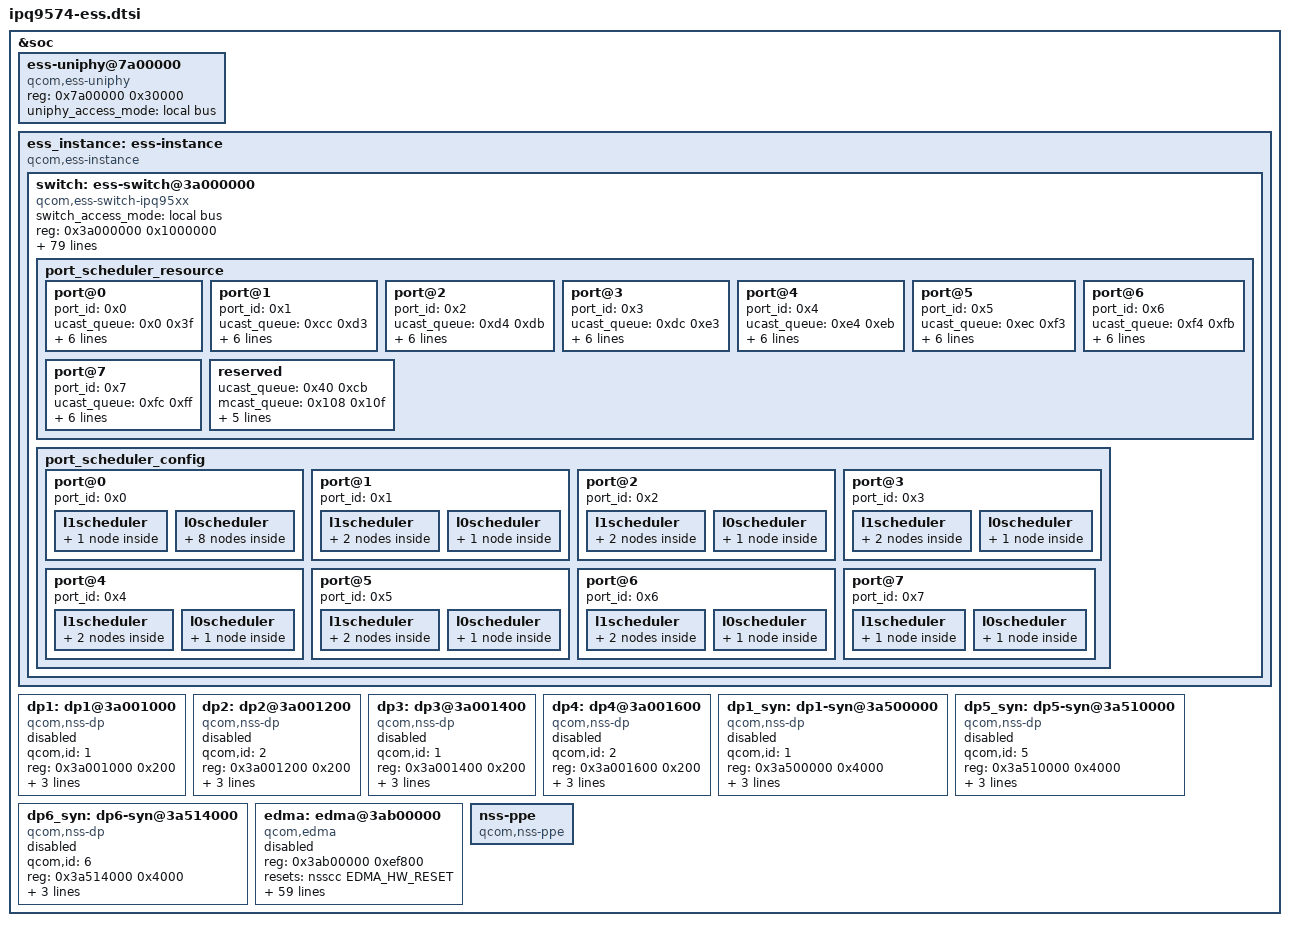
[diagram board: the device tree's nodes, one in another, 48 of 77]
#include <dt-bindings/net/qcom-ipq-ess.h>

&soc {
	ess-uniphy@7a00000 {
		compatible = "qcom,ess-uniphy";
		reg = <0x7a00000 0x30000>;
		uniphy_access_mode = "local bus";
	};

	ess_instance: ess-instance {
		compatible = "qcom,ess-instance";

		switch: ess-switch@3a000000 {
			compatible = "qcom,ess-switch-ipq95xx";
			switch_access_mode = "local bus";
			reg = <0x3a000000 0x1000000>;
			clocks = <&gcc GCC_CMN_12GPLL_AHB_CLK>,
				<&gcc GCC_CMN_12GPLL_SYS_CLK>,
				<&gcc GCC_UNIPHY0_AHB_CLK>,
				<&gcc GCC_UNIPHY0_SYS_CLK>,
				<&gcc GCC_UNIPHY1_AHB_CLK>,
				<&gcc GCC_UNIPHY1_SYS_CLK>,
				<&gcc GCC_UNIPHY2_AHB_CLK>,
				<&gcc GCC_UNIPHY2_SYS_CLK>,
				<&gcc GCC_NSSNOC_NSSCC_CLK>,
				<&gcc GCC_NSSCC_CLK>,
				<&gcc GCC_NSSNOC_SNOC_1_CLK>,
				<&gcc GCC_NSSNOC_SNOC_CLK>,
				<&nsscc NSS_CC_PORT1_MAC_CLK>,
				<&nsscc NSS_CC_PORT2_MAC_CLK>,
				<&nsscc NSS_CC_PORT3_MAC_CLK>,
				<&nsscc NSS_CC_PORT4_MAC_CLK>,
				<&nsscc NSS_CC_PORT5_MAC_CLK>,
				<&nsscc NSS_CC_PORT6_MAC_CLK>,
				<&nsscc NSS_CC_PPE_SWITCH_CLK>,
				<&nsscc NSS_CC_PPE_SWITCH_CFG_CLK>,
				<&nsscc NSS_CC_NSSNOC_PPE_CLK>,
				<&nsscc NSS_CC_NSSNOC_PPE_CFG_CLK>,
				<&nsscc NSS_CC_PPE_EDMA_CLK>,
				<&nsscc NSS_CC_PPE_EDMA_CFG_CLK>,
				<&nsscc NSS_CC_PPE_SWITCH_IPE_CLK>,
				<&nsscc NSS_CC_PPE_SWITCH_BTQ_CLK>,
				<&nsscc NSS_CC_PORT1_RX_CLK>,
				<&nsscc NSS_CC_PORT1_TX_CLK>,
				<&nsscc NSS_CC_PORT2_RX_CLK>,
				<&nsscc NSS_CC_PORT2_TX_CLK>,
				<&nsscc NSS_CC_PORT3_RX_CLK>,
				<&nsscc NSS_CC_PORT3_TX_CLK>,
				<&nsscc NSS_CC_PORT4_RX_CLK>,
				<&nsscc NSS_CC_PORT4_TX_CLK>,
				<&nsscc NSS_CC_PORT5_RX_CLK>,
				<&nsscc NSS_CC_PORT5_TX_CLK>,
				<&nsscc NSS_CC_PORT6_RX_CLK>,
				<&nsscc NSS_CC_PORT6_TX_CLK>,
				<&nsscc NSS_CC_UNIPHY_PORT1_RX_CLK>,
				<&nsscc NSS_CC_UNIPHY_PORT1_TX_CLK>,
				<&nsscc NSS_CC_UNIPHY_PORT2_RX_CLK>,
				<&nsscc NSS_CC_UNIPHY_PORT2_TX_CLK>,
				<&nsscc NSS_CC_UNIPHY_PORT3_RX_CLK>,
				<&nsscc NSS_CC_UNIPHY_PORT3_TX_CLK>,
				<&nsscc NSS_CC_UNIPHY_PORT4_RX_CLK>,
				<&nsscc NSS_CC_UNIPHY_PORT4_TX_CLK>,
				<&nsscc NSS_CC_UNIPHY_PORT5_RX_CLK>,
				<&nsscc NSS_CC_UNIPHY_PORT5_TX_CLK>,
				<&nsscc NSS_CC_UNIPHY_PORT6_RX_CLK>,
				<&nsscc NSS_CC_UNIPHY_PORT6_TX_CLK>,
				<&nsscc NSS_CC_PORT5_RX_CLK_SRC>,
				<&nsscc NSS_CC_PORT5_TX_CLK_SRC>;

			clock-names = "cmn_ahb_clk",
				"cmn_sys_clk",
				"uniphy0_ahb_clk",
				"uniphy0_sys_clk",
				"uniphy1_ahb_clk",
				"uniphy1_sys_clk",
				"uniphy2_ahb_clk",
				"uniphy2_sys_clk",
				"gcc_nssnoc_nsscc_clk",
				"gcc_nsscc_clk",
				"gcc_nssnoc_snoc_1_clk",
				"gcc_nssnoc_snoc_clk",
				"port1_mac_clk",
				"port2_mac_clk",
				"port3_mac_clk",
				"port4_mac_clk",
				"port5_mac_clk",
				"port6_mac_clk",
				"nss_ppe_clk",
				"nss_ppe_cfg_clk",
				"nssnoc_ppe_clk",
				"nssnoc_ppe_cfg_clk",
				"nss_edma_clk",
				"nss_edma_cfg_clk",
				"nss_ppe_ipe_clk",
				"nss_ppe_btq_clk",
				"nss_port1_rx_clk", "nss_port1_tx_clk",
				"nss_port2_rx_clk", "nss_port2_tx_clk",
				"nss_port3_rx_clk", "nss_port3_tx_clk",
				"nss_port4_rx_clk", "nss_port4_tx_clk",
				"nss_port5_rx_clk", "nss_port5_tx_clk",
				"nss_port6_rx_clk", "nss_port6_tx_clk",
				"uniphy0_port1_rx_clk",
				"uniphy0_port1_tx_clk",
				"uniphy0_port2_rx_clk",
				"uniphy0_port2_tx_clk",
				"uniphy0_port3_rx_clk",
				"uniphy0_port3_tx_clk",
				"uniphy0_port4_rx_clk",
				"uniphy0_port4_tx_clk",
				"uniphy0_port5_rx_clk",
				"uniphy0_port5_tx_clk",
				"uniphy2_port6_rx_clk",
				"uniphy2_port6_tx_clk",
				"nss_port5_rx_clk_src",
				"nss_port5_tx_clk_src";

			resets =<&nsscc PPE_FULL_RESET>,
				<&nsscc UNIPHY0_SOFT_RESET>,
				<&gcc GCC_UNIPHY0_XPCS_RESET>,
				<&nsscc UNIPHY_PORT5_ARES>,
				<&gcc GCC_UNIPHY1_XPCS_RESET>,
				<&nsscc UNIPHY_PORT6_ARES>,
				<&gcc GCC_UNIPHY2_XPCS_RESET>,
				<&nsscc UNIPHY_PORT1_ARES>,
				<&nsscc UNIPHY_PORT2_ARES>,
				<&nsscc UNIPHY_PORT3_ARES>,
				<&nsscc UNIPHY_PORT4_ARES>,
				<&gcc GCC_UNIPHY0_SYS_RESET>,
				<&gcc GCC_UNIPHY1_SYS_RESET>,
				<&gcc GCC_UNIPHY2_SYS_RESET>,
				<&nsscc NSSPORT1_RESET>,
				<&nsscc NSSPORT2_RESET>,
				<&nsscc NSSPORT3_RESET>,
				<&nsscc NSSPORT4_RESET>,
				<&nsscc NSSPORT5_RESET>,
				<&nsscc NSSPORT6_RESET>,
				<&nsscc PORT1_MAC_ARES>,
				<&nsscc PORT2_MAC_ARES>,
				<&nsscc PORT3_MAC_ARES>,
				<&nsscc PORT4_MAC_ARES>,
				<&nsscc PORT5_MAC_ARES>,
				<&nsscc PORT6_MAC_ARES>;

			reset-names = "ppe_rst",
				"uniphy0_soft_rst",
				"uniphy0_xpcs_rst",
				"uniphy1_soft_rst",
				"uniphy1_xpcs_rst",
				"uniphy2_soft_rst",
				"uniphy2_xpcs_rst",
				"uniphy0_port1_dis",
				"uniphy0_port2_dis",
				"uniphy0_port3_dis",
				"uniphy0_port4_dis",
				"uniphy0_sys_rst",
				"uniphy1_sys_rst",
				"uniphy2_sys_rst",
				"nss_port1_rst",
				"nss_port2_rst",
				"nss_port3_rst",
				"nss_port4_rst",
				"nss_port5_rst",
				"nss_port6_rst",
				"nss_port1_mac_rst",
				"nss_port2_mac_rst",
				"nss_port3_mac_rst",
				"nss_port4_mac_rst",
				"nss_port5_mac_rst",
				"nss_port6_mac_rst";

			bm_tick_mode = <0>; /* bm tick mode */
			tm_tick_mode = <0>; /* tm tick mode */

			switch_cpu_bmp = <ESS_PORT0>;  /* cpu port bitmap */
			switch_inner_bmp = <ESS_PORT7>; /*inner port bitmap*/
			switch_mac_mode = <MAC_MODE_DISABLED>; /* mac mode for uniphy instance0*/
			switch_mac_mode1 = <MAC_MODE_DISABLED>; /* mac mode for uniphy instance1*/
			switch_mac_mode2 = <MAC_MODE_DISABLED>; /* mac mode for uniphy instance2*/

			mdio-bus = <&mdio>;

				port_scheduler_resource {

					port@0 {
						port_id = <0x0>;
						ucast_queue = <0x0 0x3f>;
						mcast_queue = <0x100 0x107>;
						l0sp = <0x0 0x0>;
						l0cdrr = <0x0 0x7>;
						l0edrr = <0x0 0x7>;
						l1cdrr = <0x0 0x0>;
						l1edrr = <0x0 0x0>;
					};

					port@1 {
						port_id = <0x1>;
						ucast_queue = <0xcc 0xd3>;
						mcast_queue = <0x110 0x113>;
						l0sp = <0x33 0x34>;
						l0cdrr = <0x6c 0x73>;
						l0edrr = <0x6c 0x73>;
						l1cdrr = <0x17 0x18>;
						l1edrr = <0x17 0x18>;
					};

					port@2 {
						port_id = <0x2>;
						ucast_queue = <0xd4 0xdb>;
						mcast_queue = <0x114 0x117>;
						l0sp = <0x35 0x36>;
						l0cdrr = <0x74 0x7b>;
						l0edrr = <0x74 0x7b>;
						l1cdrr = <0x19 0x1a>;
						l1edrr = <0x19 0x1a>;
					};

					port@3 {
						port_id = <0x3>;
						ucast_queue = <0xdc 0xe3>;
						mcast_queue = <0x118 0x11b>;
						l0sp = <0x37 0x38>;
						l0cdrr = <0x7c 0x83>;
						l0edrr = <0x7c 0x83>;
						l1cdrr = <0x1b 0x1c>;
						l1edrr = <0x1b 0x1c>;
					};

					port@4 {
						port_id = <0x4>;
						ucast_queue = <0xe4 0xeb>;
						mcast_queue = <0x11c 0x11f>;
						l0sp = <0x39 0x3a>;
						l0cdrr = <0x84 0x8b>;
						l0edrr = <0x84 0x8b>;
						l1cdrr = <0x1d 0x1e>;
						l1edrr = <0x1d 0x1e>;
					};

					port@5 {
						port_id = <0x5>;
						ucast_queue = <0xec 0xf3>;
						mcast_queue = <0x120 0x123>;
						l0sp = <0x3b 0x3c>;
						l0cdrr = <0x8c 0x93>;
						l0edrr = <0x8c 0x93>;
						l1cdrr = <0x1f 0x20>;
						l1edrr = <0x1f 0x20>;
					};

					port@6 {
						port_id = <0x6>;
						ucast_queue = <0xf4 0xfb>;
						mcast_queue = <0x124 0x127>;
						l0sp = <0x3d 0x3e>;
						l0cdrr = <0x94 0x9b>;
						l0edrr = <0x94 0x9b>;
						l1cdrr = <0x21 0x22>;
						l1edrr = <0x21 0x22>;
					};

					port@7 {
						port_id = <0x7>;
						ucast_queue = <0xfc 0xff>;
						mcast_queue = <0x128 0x12b>;
						l0sp = <0x3f 0x3f>;
						l0cdrr = <0x9c 0x9f>;
						l0edrr = <0x9c 0x9f>;
						l1cdrr = <0x23 0x23>;
						l1edrr = <0x23 0x23>;
					};

					reserved {
						ucast_queue = <0x40 0xcb>;
						mcast_queue = <0x108 0x10f>;
						l0sp = <0x1 0x32>;
						l0cdrr = <0x8 0x6b>;
						l0edrr = <0x8 0x6b>;
						l1cdrr = <0x1 0x16>;
						l1edrr = <0x1 0x16>;
					};
				};

				port_scheduler_config {

					port@0 {
						port_id = <0x0>;

						l1scheduler {

							group@0 {
								sp = <0x0>;
								cfg = <0x0 0x0 0x0 0x0>;
							};
						};

						l0scheduler {

							group@0 {
								ucast_queue = <0x0>;
								ucast_loop_pri = <0x8>;
								mcast_queue = <0x100>;
								cfg = <0x0 0x0 0x0 0x0 0x0>;
							};

							group@1 {
								ucast_queue = <0x8>;
								ucast_loop_pri = <0x8>;
								mcast_queue = <0x101>;
								cfg = <0x0 0x0 0x0 0x0 0x0>;
							};

							group@2 {
								ucast_queue = <0x10>;
								ucast_loop_pri = <0x8>;
								mcast_queue = <0x102>;
								cfg = <0x0 0x0 0x0 0x0 0x0>;
							};

							group@3 {
								ucast_queue = <0x18>;
								ucast_loop_pri = <0x8>;
								mcast_queue = <0x103>;
								cfg = <0x0 0x0 0x0 0x0 0x0>;
							};

							group@4 {
								ucast_queue = <0x20>;
								ucast_loop_pri = <0x8>;
								mcast_queue = <0x104>;
								cfg = <0x0 0x0 0x0 0x0 0x0>;
							};

							group@5 {
								ucast_queue = <0x28>;
								ucast_loop_pri = <0x8>;
								mcast_queue = <0x105>;
								cfg = <0x0 0x0 0x0 0x0 0x0>;
							};

							group@6 {
								ucast_queue = <0x30>;
								ucast_loop_pri = <0x8>;
								mcast_queue = <0x106>;
								cfg = <0x0 0x0 0x0 0x0 0x0>;
							};

							group@7 {
								ucast_queue = <0x38>;
								ucast_loop_pri = <0x8>;
								mcast_queue = <0x107>;
								cfg = <0x0 0x0 0x0 0x0 0x0>;
							};
						};
					};

					port@1 {
						port_id = <0x1>;

						l1scheduler {

							group@0 {
								sp = <0x33>;
								cfg = <0x0 0x17 0x0 0x17>;
							};

							group@1 {
								sp = <0x34>;
								cfg = <0x1 0x18 0x1 0x18>;
							};
						};

						l0scheduler {

							group@0 {
								ucast_queue = <0xcc>;
								ucast_loop_pri = <0x8>;
								ucast_max_pri = <0x4>;
								mcast_queue = <0x110>;
								mcast_loop_pri = <0x4>;
								cfg = <0x33 0x0 0x6c 0x0 0x6c>;
							};
						};
					};

					port@2 {
						port_id = <0x2>;

						l1scheduler {

							group@0 {
								sp = <0x35>;
								cfg = <0x0 0x19 0x0 0x19>;
							};

							group@1 {
								sp = <0x36>;
								cfg = <0x1 0x1a 0x1 0x1a>;
							};
						};

						l0scheduler {

							group@0 {
								ucast_queue = <0xd4>;
								ucast_loop_pri = <0x8>;
								ucast_max_pri = <0x4>;
								mcast_queue = <0x114>;
								mcast_loop_pri = <0x4>;
								cfg = <0x35 0x0 0x74 0x0 0x74>;
							};
						};
					};

					port@3 {
						port_id = <0x3>;

						l1scheduler {

							group@0 {
								sp = <0x37>;
								cfg = <0x0 0x1b 0x0 0x1b>;
							};

							group@1 {
								sp = <0x38>;
								cfg = <0x1 0x1c 0x1 0x1c>;
							};
						};

						l0scheduler {

							group@0 {
								ucast_queue = <0xdc>;
								ucast_loop_pri = <0x8>;
								ucast_max_pri = <0x4>;
								mcast_queue = <0x118>;
								mcast_loop_pri = <0x4>;
								cfg = <0x37 0x0 0x7c 0x0 0x7c>;
							};
						};
					};

					port@4 {
						port_id = <0x4>;

						l1scheduler {

							group@0 {
								sp = <0x39>;
								cfg = <0x0 0x1d 0x0 0x1d>;
							};

							group@1 {
								sp = <0x3a>;
								cfg = <0x1 0x1e 0x1 0x1e>;
							};
						};

						l0scheduler {

							group@0 {
								ucast_queue = <0xe4>;
								ucast_loop_pri = <0x8>;
								ucast_max_pri = <0x4>;
								mcast_queue = <0x11c>;
								mcast_loop_pri = <0x4>;
								cfg = <0x39 0x0 0x84 0x0 0x84>;
							};
						};
					};

					port@5 {
						port_id = <0x5>;

						l1scheduler {

							group@0 {
								sp = <0x3b>;
								cfg = <0x0 0x1f 0x0 0x1f>;
							};

							group@1 {
								sp = <0x3c>;
								cfg = <0x1 0x20 0x1 0x20>;
							};
						};

						l0scheduler {

							group@0 {
								ucast_queue = <0xec>;
								ucast_loop_pri = <0x8>;
								ucast_max_pri = <0x4>;
								mcast_queue = <0x120>;
								mcast_loop_pri = <0x4>;
								cfg = <0x3b 0x0 0x8c 0x0 0x8c>;
							};
						};
					};

					port@6 {
						port_id = <0x6>;

						l1scheduler {

							group@0 {
								sp = <0x3d>;
								cfg = <0x0 0x21 0x0 0x21>;
							};

							group@1 {
								sp = <0x3e>;
								cfg = <0x1 0x22 0x1 0x22>;
							};
						};

						l0scheduler {

							group@0 {
								ucast_queue = <0xf4>;
								ucast_loop_pri = <0x8>;
								ucast_max_pri = <0x4>;
								mcast_queue = <0x124>;
								mcast_loop_pri = <0x4>;
								cfg = <0x3d 0x0 0x94 0x0 0x94>;
							};
						};
					};

					port@7 {
						port_id = <0x7>;

						l1scheduler {

							group@0 {
								sp = <0x3f>;
								cfg = <0x0 0x23 0x0 0x23>;
							};
						};

						l0scheduler {

							group@0 {
								ucast_queue = <0xfc>;
								ucast_loop_pri = <0x4>;
								ucast_max_pri = <0x4>;
								mcast_queue = <0x128>;
								mcast_loop_pri = <0x4>;
								cfg = <0x3f 0x0 0x9c 0x0 0x9c>;
							};
						};
					};
				};
		};
	};

	dp1: dp1@3a001000 {
		device_type = "network";
		compatible = "qcom,nss-dp";
		qcom,id = <1>;
		reg = <0x3a001000 0x200>;
		qcom,mactype = <0>;
		local-mac-address = [000000000000];
		phy-mode = "sgmii";
		status = "disabled";
	};

	dp2: dp2@3a001200 {
		device_type = "network";
		compatible = "qcom,nss-dp";
		qcom,id = <2>;
		reg = <0x3a001200 0x200>;
		qcom,mactype = <0>;
		local-mac-address = [000000000000];
		phy-mode = "sgmii";
		status = "disabled";
	};

	dp3: dp3@3a001400 {
		device_type = "network";
		compatible = "qcom,nss-dp";
		qcom,id = <1>;
		reg = <0x3a001400 0x200>;
		qcom,mactype = <0>;
		local-mac-address = [000000000000];
		phy-mode = "sgmii";
		status = "disabled";
	};

	dp4: dp4@3a001600 {
		device_type = "network";
		compatible = "qcom,nss-dp";
		qcom,id = <2>;
		reg = <0x3a001600 0x200>;
		qcom,mactype = <0>;
		local-mac-address = [000000000000];
		phy-mode = "sgmii";
		status = "disabled";
	};

	dp1_syn: dp1-syn@3a500000 {
		device_type = "network";
		compatible = "qcom,nss-dp";
		qcom,id = <1>;
		reg = <0x3a500000 0x4000>;
		qcom,mactype = <1>;
		local-mac-address = [000000000000];
		phy-mode = "sgmii";
		status = "disabled";
	};

	dp5_syn: dp5-syn@3a510000 {
		device_type = "network";
		compatible = "qcom,nss-dp";
		qcom,id = <5>;
		reg = <0x3a510000 0x4000>;
		qcom,mactype = <1>;
		local-mac-address = [000000000000];
		phy-mode = "sgmii";
		status = "disabled";
	};

	dp6_syn: dp6-syn@3a514000 {
		device_type = "network";
		compatible = "qcom,nss-dp";
		qcom,id = <6>;
		reg = <0x3a514000 0x4000>;
		qcom,mactype = <1>;
		local-mac-address = [000000000000];
		phy-mode = "sgmii";
		status = "disabled";
	};

	edma: edma@3ab00000 {
		compatible = "qcom,edma";
		reg = <0x3ab00000 0xef800>;
		reg-names = "edma-reg-base";
		resets = <&nsscc EDMA_HW_RESET>;
		reset-names = "edma_rst";
		status = "disabled";
		clocks = <&nsscc NSS_CC_NSS_CSR_CLK>,
			 <&nsscc NSS_CC_NSSNOC_NSS_CSR_CLK>,
			 <&nsscc NSS_CC_IMEM_QSB_CLK>,
			 <&nsscc NSS_CC_NSSNOC_IMEM_QSB_CLK>,
			 <&nsscc NSS_CC_IMEM_AHB_CLK>,
			 <&nsscc NSS_CC_NSSNOC_IMEM_AHB_CLK>,
			 <&gcc GCC_MEM_NOC_NSSNOC_CLK>,
			 <&gcc GCC_NSS_TBU_CLK>,
			 <&gcc GCC_NSS_TS_CLK>,
			 <&gcc GCC_NSSCC_CLK>,
			 <&gcc GCC_NSSCFG_CLK>,
			 <&gcc GCC_NSSNOC_ATB_CLK>,
			 <&gcc GCC_NSSNOC_MEM_NOC_1_CLK>,
			 <&gcc GCC_NSSNOC_MEMNOC_CLK>,
			 <&gcc GCC_NSSNOC_NSSCC_CLK>,
			 <&gcc GCC_NSSNOC_PCNOC_1_CLK>,
			 <&gcc GCC_NSSNOC_QOSGEN_REF_CLK>,
			 <&gcc GCC_NSSNOC_SNOC_1_CLK>,
			 <&gcc GCC_NSSNOC_SNOC_CLK>,
			 <&gcc GCC_NSSNOC_TIMEOUT_REF_CLK>,
			 <&gcc GCC_NSSNOC_XO_DCD_CLK>;
		clock-names = "nss-csr-clk", "nss-nssnoc-csr-clk",
			      "nss-imem-qsb-clk", "nss-nssnoc-imem-qsb-clk",
			      "nss-imem-ahb-clk", "nss-nssnoc-imem-ahb-clk",
			      "nss-mem-noc-nssnoc-clk", "nss-tbu-clk", "nss-ts-clk",
			      "nss-nsscc-clk", "nss-nsscfg-clk", "nss-nsscnoc-atb-clk",
			      "nss-nssnoc-mem-noc-1-clk", "nss-nssnoc-memnoc-clk", "nss-nssnoc-nsscc-clk",
			      "nss-nssnoc-pcnoc-1-clk", "nss-nssnoc-qosgen-ref-clk", "nss-nssnoc-snoc-1-clk",
			      "nss-nssnoc-snoc-clk", "nss-nssnoc-timeout-ref-clk", "nss-nssnoc-xo-dcd-clk";

		qcom,txdesc-ring-start = <4>;		/* Tx desc ring start ID */
		qcom,txdesc-rings = <28>;		/* Total number of Tx desc rings to be provisioned */

		qcom,txcmpl-ring-start = <4>;		/* Tx complete ring start ID */
		qcom,txcmpl-rings = <28>;		/* Total number of Tx complete rings to be provisioned */

		qcom,rxfill-ring-start = <4>;		/* Rx fill ring start ID */
		qcom,rxfill-rings = <4>;		/* Total number of Rx fill rings to be provisioned */

		qcom,rxdesc-ring-start = <20>;		/* Rx desc ring start ID */
		qcom,rxdesc-rings = <4>;		/* Total number of Rx desc rings to be provisioned */
		qcom,rx-page-mode = <0>;		/* Rx fill ring page mode */

		qcom,tx-map-priority-level = <1>;	/* Tx priority level per port */
		qcom,rx-map-priority-level = <1>;	/* Rx priority level per core */
		qcom,ppeds-num = <4>;			/* Number of PPEDS nodes */
		/* PPE-DS node format: <Rx-fill Tx-cmpl Rx Tx Queue-base Queue-count> */
		qcom,ppeds-map = <0x1 0x1 0x1 0x1 0x4 0x4>,
				 <0x2 0x2 0x2 0x2 0x8 0x4>,
				 <0x3 0x3 0x3 0x3 0xc 0x4>;
//		qcom,ppeds-map = <1 1 1 1 32 8>,	/* PPEDS Node#0 ring and queue map */
//				<2 2 2 2 40 8>,		/* PPEDS Node#1 ring and queue map */
//				<3 3 3 3 48 8>,		/* PPEDS Node#2 ring and queue map */
//				<0 0 0 0 56 8>;		/* PPEDS Node#3 ring and queue map */
		qcom,txdesc-map = <8 9 10 11>,		/* Port0 per-core Tx ring map */
				<12 13 14 15>,		/* Port1 per-core Tx ring map */
				<16 17 18 19>,		/* Port2 per-core Tx ring map */
				<20 21 22 23>,		/* Port3 per-core Tx ring map */
				<24 25 26 27>,		/* Port4 per-core Tx ring map */
				<28 29 30 31>,		/* Port5 per-core Tx ring map */
				<4 5 6 7>;		/* Used only for VP" */
		qcom,txdesc-fc-grp-map = <1 2 3 4 5 6>;	/* Per GMAC flow control group map */
		qcom,rxfill-map = <4 5 6 7>;		/* Per-core Rx fill ring map */
		qcom,rxdesc-map = <20 21 22 23>;	/* Per-core Rx desc ring map */
		qcom,rx-queue-start = <0>;		/* Rx queue start */

		qcom,rx-ring-queue-map = <0 8 16 24>,	/* Priority 0 queues per-core Rx ring map */
				<1 9 17 25>,		/* Priority 1 queues per-core Rx ring map */
				<2 10 18 26>,		/* Priority 2 queues per-core Rx ring map */
				<3 11 19 27>,		/* Priority 3 queues per-core Rx ring map */
				<4 12 20 28>,		/* Priority 4 queues per-core Rx ring map */
				<5 13 21 29>,		/* Priority 5 queues per-core Rx ring map */
				<6 14 22 30>,		/* Priority 6 queues per-core Rx ring map */
				<7 15 23 31>;		/* Priority 7 queues per-core Rx ring map */
		qcom,txdesc_point_offload_ring = <0>;		/* Txdesc point offlaod ring */
		qcom,txcmpl_point_offload_ring = <0>;		/* Txcmpl point offlaod ring */
		qcom,rxfill_point_offload_ring = <0>;		/* Rxfill point offlaod ring */
		qcom,rxdesc_point_offload_ring = <0>;		/* Rxdesc point offlaod ring */
		qcom,vp-id = <8>;			/* Virtual port dummy MAC Id */
		interrupts = <0 367 4>,			/* Tx complete ring id #4 IRQ info */
			   <0 368 4>,			/* Tx complete ring id #5 IRQ info */
			   <0 369 4>,			/* Tx complete ring id #6 IRQ info */
			   <0 370 4>,			/* Tx complete ring id #7 IRQ info */
			   <0 371 4>,			/* Tx complete ring id #8 IRQ info */
			   <0 372 4>,			/* Tx complete ring id #9 IRQ info */
			   <0 373 4>,			/* Tx complete ring id #10 IRQ info */
			   <0 374 4>,			/* Tx complete ring id #11 IRQ info */
			   <0 375 4>,			/* Tx complete ring id #12 IRQ info */
			   <0 376 4>,			/* Tx complete ring id #13 IRQ info */
			   <0 377 4>,			/* Tx complete ring id #14 IRQ info */
			   <0 378 4>,			/* Tx complete ring id #15 IRQ info */
			   <0 379 4>,			/* Tx complete ring id #16 IRQ info */
			   <0 380 4>,			/* Tx complete ring id #17 IRQ info */
			   <0 381 4>,			/* Tx complete ring id #18 IRQ info */
			   <0 382 4>,			/* Tx complete ring id #19 IRQ info */
			   <0 383 4>,			/* Tx complete ring id #20 IRQ info */
			   <0 384 4>,			/* Tx complete ring id #21 IRQ info */
			   <0 509 4>,			/* Tx complete ring id #22 IRQ info */
			   <0 508 4>,			/* Tx complete ring id #23 IRQ info */
			   <0 507 4>,			/* Tx complete ring id #24 IRQ info */
			   <0 506 4>,			/* Tx complete ring id #25 IRQ info */
			   <0 505 4>,			/* Tx complete ring id #26 IRQ info */
			   <0 504 4>,			/* Tx complete ring id #27 IRQ info */
			   <0 503 4>,			/* Tx complete ring id #28 IRQ info */
			   <0 502 4>,			/* Tx complete ring id #29 IRQ info */
			   <0 501 4>,			/* Tx complete ring id #30 IRQ info */
			   <0 500 4>,			/* Tx complete ring id #31 IRQ info */

			   <0 351 4>,			/* Rx desc ring id #20 IRQ info */
			   <0 352 4>,			/* Rx desc ring id #21 IRQ info */
			   <0 353 4>,			/* Rx desc ring id #22 IRQ info */
			   <0 354 4>,			/* Rx desc ring id #23 IRQ info */

			   <0 499 4>,			/* Misc error IRQ info */

			   <0 364 4>,			/* PPEDS Node #0(TxComp ring id #1) TxComplete IRQ info */
			   <0 332 4>,			/* PPEDS Node #0(Rx Desc ring id #1) Rx Desc IRQ info */
			   <0 356 4>,			/* PPEDS Node #0(RxFill Desc ring id #1) Rx Fill IRQ info */
			   <0 365 4>,			/* PPEDS Node #1(TxComp ring id #2) TxComplete IRQ info */
			   <0 333 4>,			/* PPEDS Node #1(Rx Desc ring id #2) Rx Desc IRQ info */
			   <0 357 4>,			/* PPEDS Node #1(RxFill Desc ring id #2) Rx Fill IRQ info */
			   <0 366 4>,			/* PPEDS Node #2(TxComp ring id #3) TxComplete IRQ info */
			   <0 334 4>,			/* PPEDS Node #2(Rx Desc ring id #3) Rx Desc IRQ info */
			   <0 358 4>,			/* PPEDS Node #2(RxFill Desc ring id #3) Rx Fill IRQ info */
			   <0 363 4>,			/* PPEDS Node #3(TxComp ring id #0) TxComplete IRQ info */
			   <0 331 4>,			/* PPEDS Node #3(Rx Desc ring id #0) Rx Desc IRQ info */
			   <0 355 4>;			/* PPEDS Node #3(RxFill Desc ring id #0) Rx Fill IRQ info */
	};

	nss-ppe {
		compatible = "qcom,nss-ppe";
	};
};
